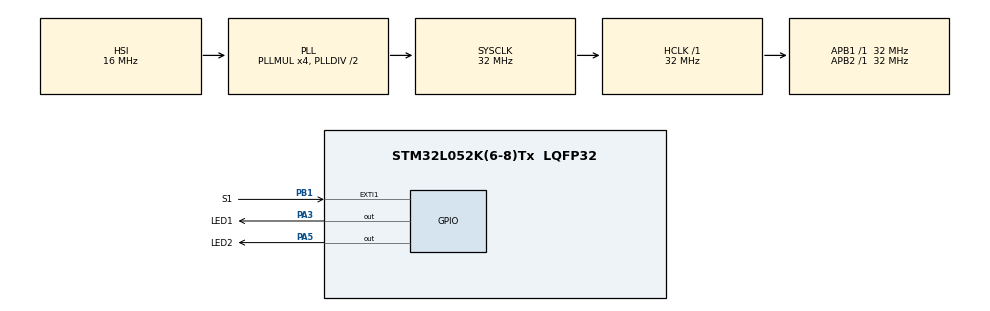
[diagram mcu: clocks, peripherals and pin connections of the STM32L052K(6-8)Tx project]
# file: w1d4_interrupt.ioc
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Mcu.Family=STM32L0
Mcu.Name=STM32L052K(6-8)Tx
Mcu.Package=LQFP32
NVIC.EXTI0_1_IRQn=true\:0\:0\:false\:false\:true\:true\:true
NVIC.TIM6_DAC_IRQn=true\:0\:0\:false\:false\:true\:true\:true
PA13.Mode=Serial_Wire
PA13.Signal=SYS_SWDIO
PA14.Mode=Serial_Wire
PA14.Signal=SYS_SWCLK
PA3.GPIO_Label=LED1
PA3.Signal=GPIO_Output
PA5.GPIO_Label=LED2
PA5.Signal=GPIO_Output
PB1.GPIO_Label=S1
PB1.GPIO_PuPd=GPIO_PULLUP
PB1.Signal=GPXTI1
ProjectManager.HeapSize=0x200
ProjectManager.StackSize=0x400
ProjectManager.TargetToolchain=STM32CubeIDE
RCC.AHBFreq_Value=32000000
RCC.APB1Freq_Value=32000000
RCC.APB1TimFreq_Value=32000000
RCC.APB2Freq_Value=32000000
RCC.APB2TimFreq_Value=32000000
RCC.HCLKFreq_Value=32000000
RCC.HSI16_VALUE=16000000
RCC.HSI48_VALUE=48000000
RCC.HSI_VALUE=16000000
RCC.LSE_VALUE=32768
RCC.MSI_VALUE=2097000
RCC.PLLMUL=RCC_PLLMUL_4
RCC.SYSCLKFreq_VALUE=32000000
RCC.SYSCLKSource=RCC_SYSCLKSOURCE_PLLCLK
RCC.VCOOutputFreq_Value=64000000
TIM6.Period=500-1
TIM6.Prescaler=32000-1
VP_TIM6_VS_ClockSourceINT.Mode=Enable_Timer
board=custom

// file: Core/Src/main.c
/* USER CODE BEGIN Header */
/**
 ******************************************************************************
 * @file           : main.c
 * @brief          : Main program body
 ******************************************************************************
 * @attention
 *
 * Copyright (c) 2021 STMicroelectronics.
 * All rights reserved.
 *
 * This software is licensed under terms that can be found in the LICENSE file
 * in the root directory of this software component.
 * If no LICENSE file comes with this software, it is provided AS-IS.
 *
 ******************************************************************************
 */
/* USER CODE END Header */
#include "main.h"

/* USER CODE BEGIN Includes */
#include "App.h"
/* USER CODE END Includes */

TIM_HandleTypeDef htim6;

void SystemClock_Config(void);
static void MX_GPIO_Init(void);
static void MX_TIM6_Init(void);

int main(void)
{

  /* MCU Configuration--------------------------------------------------------*/

  /* Reset of all peripherals, Initializes the Flash interface and the Systick. */
  HAL_Init();

  /* Configure the system clock */
  SystemClock_Config();

  /* Initialize all configured peripherals */
  MX_GPIO_Init();
  MX_TIM6_Init();
  HAL_TIM_Base_Start_IT(&htim6);

  /* Infinite loop */
  /* USER CODE BEGIN WHILE */
	while (1) {
		appLoop();
    /* USER CODE END WHILE */

	}
}

void SystemClock_Config(void)
{
  RCC_OscInitTypeDef RCC_OscInitStruct = {0};
  RCC_ClkInitTypeDef RCC_ClkInitStruct = {0};

  /** Configure the main internal regulator output voltage
  */
  __HAL_PWR_VOLTAGESCALING_CONFIG(PWR_REGULATOR_VOLTAGE_SCALE1);
  /** Initializes the RCC Oscillators according to the specified parameters
  * in the RCC_OscInitTypeDef structure.
  */
  RCC_OscInitStruct.OscillatorType = RCC_OSCILLATORTYPE_HSI;
  RCC_OscInitStruct.HSIState = RCC_HSI_ON;
  RCC_OscInitStruct.HSICalibrationValue = RCC_HSICALIBRATION_DEFAULT;
  RCC_OscInitStruct.PLL.PLLState = RCC_PLL_ON;
  RCC_OscInitStruct.PLL.PLLSource = RCC_PLLSOURCE_HSI;
  RCC_OscInitStruct.PLL.PLLMUL = RCC_PLLMUL_4;
  RCC_OscInitStruct.PLL.PLLDIV = RCC_PLLDIV_2;
  if (HAL_RCC_OscConfig(&RCC_OscInitStruct) != HAL_OK)
  {
    Error_Handler();
  }
  /** Initializes the CPU, AHB and APB buses clocks
  */
  RCC_ClkInitStruct.ClockType = RCC_CLOCKTYPE_HCLK|RCC_CLOCKTYPE_SYSCLK
                              |RCC_CLOCKTYPE_PCLK1|RCC_CLOCKTYPE_PCLK2;
  RCC_ClkInitStruct.SYSCLKSource = RCC_SYSCLKSOURCE_PLLCLK;
  RCC_ClkInitStruct.AHBCLKDivider = RCC_SYSCLK_DIV1;
  RCC_ClkInitStruct.APB1CLKDivider = RCC_HCLK_DIV1;
  RCC_ClkInitStruct.APB2CLKDivider = RCC_HCLK_DIV1;

  if (HAL_RCC_ClockConfig(&RCC_ClkInitStruct, FLASH_LATENCY_1) != HAL_OK)
  {
    Error_Handler();
  }
}

static void MX_TIM6_Init(void)
{

  TIM_MasterConfigTypeDef sMasterConfig = {0};

  htim6.Instance = TIM6;
  htim6.Init.Prescaler = 32000-1;
  htim6.Init.CounterMode = TIM_COUNTERMODE_UP;
  htim6.Init.Period = 500-1;
  htim6.Init.AutoReloadPreload = TIM_AUTORELOAD_PRELOAD_DISABLE;
  if (HAL_TIM_Base_Init(&htim6) != HAL_OK)
  {
    Error_Handler();
  }
  sMasterConfig.MasterOutputTrigger = TIM_TRGO_RESET;
  sMasterConfig.MasterSlaveMode = TIM_MASTERSLAVEMODE_DISABLE;
  if (HAL_TIMEx_MasterConfigSynchronization(&htim6, &sMasterConfig) != HAL_OK)
  {
    Error_Handler();
  }

}

static void MX_GPIO_Init(void)
{
  GPIO_InitTypeDef GPIO_InitStruct = {0};

  /* GPIO Ports Clock Enable */
  __HAL_RCC_GPIOA_CLK_ENABLE();
  __HAL_RCC_GPIOB_CLK_ENABLE();

  /*Configure GPIO pin Output Level */
  HAL_GPIO_WritePin(GPIOA, LED1_Pin|LED2_Pin, GPIO_PIN_RESET);

  /*Configure GPIO pins : LED1_Pin LED2_Pin */
  GPIO_InitStruct.Pin = LED1_Pin|LED2_Pin;
  GPIO_InitStruct.Mode = GPIO_MODE_OUTPUT_PP;
  GPIO_InitStruct.Pull = GPIO_NOPULL;
  GPIO_InitStruct.Speed = GPIO_SPEED_FREQ_LOW;
  HAL_GPIO_Init(GPIOA, &GPIO_InitStruct);

  /*Configure GPIO pin : S1_Pin */
  GPIO_InitStruct.Pin = S1_Pin;
  GPIO_InitStruct.Mode = GPIO_MODE_IT_RISING;
  GPIO_InitStruct.Pull = GPIO_PULLUP;
  HAL_GPIO_Init(S1_GPIO_Port, &GPIO_InitStruct);

  /* EXTI interrupt init*/
  HAL_NVIC_SetPriority(EXTI0_1_IRQn, 0, 0);
  HAL_NVIC_EnableIRQ(EXTI0_1_IRQn);

}

void Error_Handler(void)
{
	__disable_irq();
	while (1) {
	}
}
